# A33G53x register map
Vendor: ABOV Semiconductor Co., Ltd.; File version: 0.1
CPU: CM3 r1p0, little endian, no MPU, no FPU, 3 interrupt priority bits
Registers are 32-bit, read-write, reset 0x0 unless marked. A register's access mark holds for its fields unless they carry their own. Offsets are from the block's base; [hi:lo] are bit positions; {n}, {i} and the like mark numbered series.

## PMU — POWER MANAGEMENT UNIT
Base 0x40000000
0x00 IDR ro reset 0xCEDA0000 — Chip ID Register
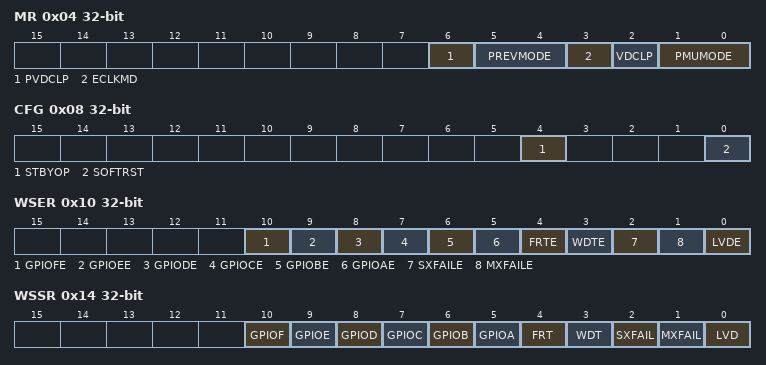
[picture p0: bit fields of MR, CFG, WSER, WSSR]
0x04 MR — PMU Mode Register
  [6] PVDCLP ro — VDC low power status of the previous state
  [5:4] PREVMODE ro — The previous MCU status before reset
  [3] ECLKMD wo — Power-down mode, External Clock Oscillator(Main/Sub) is automatically OFF or set to allow user setting
  [2] VDCLP wo — Power-down mode, VDC switched to low-power
  [1:0] PMUMODE — Indicates the current operating mode of the MCU, that the value of this mode when you write. However, writing '11' is prohibited.
0x08 CFG — PMU CONFIGURATION REGISTER
  [4] STBYOP — Output polarity of STBY pin
  [0] SOFTRST wo — Setting for internal soft-reset
0x10 WSER — PMU Wake-up Source Enable Register
  [10] GPIOFE — Setting of the wake-up by GPIOF (PD SLEEP)
  [9] GPIOEE — Setting of the wake-up by GPIOE (PD SLEEP)
  [8] GPIODE — Setting of the wake-up by GPIOD (PD SLEEP)
  [7] GPIOCE — Setting of the wake-up by GPIOC (PD SLEEP)
  [6] GPIOBE — Setting of the wake-up by GPIOB (PD SLEEP)
  [5] GPIOAE — Setting of the wake-up by GPIO (PD SLEEP)
  [4] FRTE — Setting of the wake-up by FRT (PD SLEEP)
  [3] WDTE — Setting of the wake-up by WDT (PD SLEEP)
  [2] SXFAILE — Setting of the wake-up by the Sub OSC Fail Event(SLEEP)Setting value of the wake-up by LVD (SLEEP)
  [1] MXFAILE — Setting of the wake-up by Main OSC-fail event(SLEEP)Setting value of the wake-up by Sub OSC Fail Event (SLEEP)
  [0] LVDE — Setting of the wake-up by LVD (SLEEP)Setting value of the wake-up by Main OSC Fail Event (SLEEP)
0x14 WSSR ro — PMU Wak-up Source Status Register
  [10] GPIOF — Status flag of the wake-up by GPIOF
  [9] GPIOE — Status flag of the wake-up by GPIOE
  [8] GPIOD — Status flag of the wake-up by GPIOD
  [7] GPIOC — Status flag of the wake-up by GPIOC
  [6] GPIOB — Status flag of the wake-up by GPIOB
  [5] GPIOA — Status flag of the wake-up by GPIOA
  [4] FRT — Status flag of the wake-up by FRT
  [3] WDT — Status flag of the wake-up by WDT
  [2] SXFAIL — Status flag of the wake-up by Sub OSC Fail Event
  [1] MXFAIL — Status flag of the wake-up by Main OSC Fail Event
  [0] LVD — Status flag of the wake-up by LVD
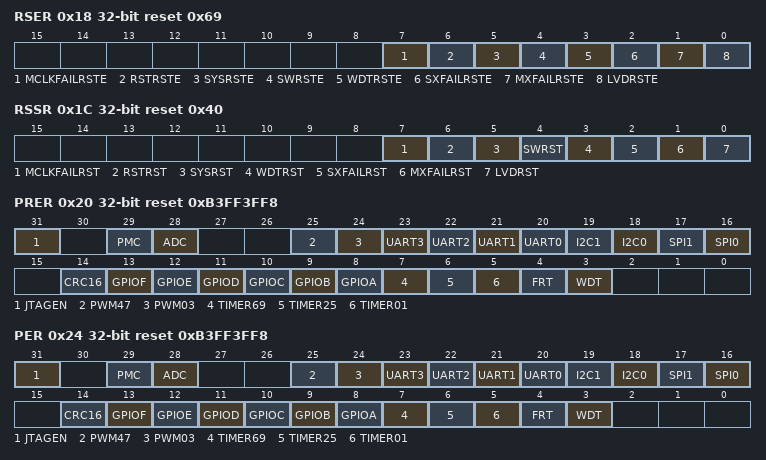
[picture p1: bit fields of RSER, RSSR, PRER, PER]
0x18 RSER reset 0x69 (reset mask 0xFB) — Reset Source Enable Register
  [7] MCLKFAILRSTE — Enable/Disable Main Clock Oscillator pin reset
  [6] RSTRSTE — Enable/Disable external nRESET pin reset
  [5] SYSRSTE — Enable/Disable SystemReset from the core
  [4] SWRSTE — Enable/Disable Software Reset in PMUCFGR
  [3] WDTRSTE — Enable/Disable WDT reset
  [2] SXFAILRSTE — Enable/Disable auxiliary oscillator failure reset
  [1] MXFAILRSTE — Enable/Disable auxiliary oscillator failure reset
  [0] LVDRSTE — Enable/Disable LVD reset
0x1C RSSR reset 0x40 (reset mask 0xFB) — Reset Source Status Register
  [7] MCLKFAILRST — Occurrence of Main Clock Oscillator pin reset
  [6] RSTRST — Occurrence of external nRESET pin reset
  [5] SYSRST — Occurrence of SystemReset from the core
  [4] SWRST — Occurrence of Software Reset in PMUCFGR
  [3] WDTRST — Occurrence of WDT reset
  [2] SXFAILRST — Occurrence of auxiliary oscillator failure reset
  [1] MXFAILRST — Occurrence of auxiliary oscillator failure reset
  [0] LVDRST — Occurrence of LVD reset
0x20 PRER reset 0xB3FF3FF8 — PMU Peripheral Event Reset Register
  [31] JTAGEN — Enable JTAG reset
  [29] PMC — Enable PMC (Port Map Controller) reset
  [28] ADC — Enable ADC reset
  [25] PWM47 — Enable PWM4, 5,6,7 reset
  [24] PWM03 — Enable PWM0, 1,2,3 reset
  [n+20] UART{n} (n=0..3) — Enable UART{n} reset
  [19] I2C1 — Enable I2C1 reset
  [18] I2C0 — Enable I2C0 reset
  [17] SPI1 — Enable SPI1 reset
  [16] SPI0 — Enable SPI0 reset
  [14] CRC16 — Enable CRC reset
  [13] GPIOF — Enable GPIOF reset
  [12] GPIOE — Enable GPIOE reset
  [11] GPIOD — Enable GPIOD reset
  [10] GPIOC — Enable GPIOC reset
  [9] GPIOB — Enable GPIOB reset
  [8] GPIOA — Enable GPIOA reset
  [7] TIMER69 — Enable TIMER6, 7,8,9 reset
  [6] TIMER25 — Enable TIMER2, 3,4,5 reset
  [5] TIMER01 — Enable TIMER0, 1 reset
  [4] FRT — Enble Free-run Timer reset
  [3] WDT — Enabled Watchdog Timer reset
0x24 PER reset 0xB3FF3FF8 — PMU Perpheral Enable Register
  [31] JTAGEN — JTAG enable - reset
  [29] PMC — Enable-Reset PMC
  [28] ADC — Enable-Reset ADC
  [25] PWM47 — Enable-Reset PWM4, 5,6,7
  [24] PWM03 — Enable-Reset PWM0, 1,2,3
  [n+20] UART{n} (n=0..3) — Enable-Reset UART{n}
  [19] I2C1 — Enable-Reset I2C1
  [18] I2C0 — Enable-Reset I2C0
  [17] SPI1 — Enable-Reset SPI1
  [16] SPI0 — Enable-Reset SPI0
  [14] CRC16 — Enable-Reset CRC16
  [13] GPIOF — Enable-Reset PMC_F, GPIOF
  [12] GPIOE — Enable-Reset PMC_E, GPIOE
  [11] GPIOD — Enable-Reset PMC_D, GPIOD
  [10] GPIOC — Enable-Reset PMC_C, GPIOC
  [9] GPIOB — Enable-Reset PMC_B, GPIOB
  [8] GPIOA — Enable-Reset PMC_A, GPIOA
  [7] TIMER69 — Enable-Reset TIMER6, 7,8,9
  [6] TIMER25 — Enable-Reset TIMER2, 3,4,5
  [5] TIMER01 — Enable-Reset TIMER0, 1
  [4] FRT — Enable-Reset Free-run Timer
  [3] WDT — Enable-Reset Watch-dog Timer
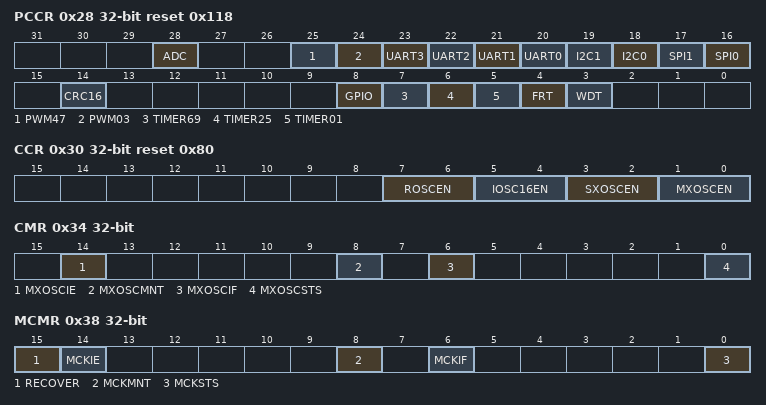
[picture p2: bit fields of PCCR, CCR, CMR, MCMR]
0x28 PCCR reset 0x118 (reset mask 0x11FF41F8) — PMU Peripheral Clock Control Register
  [28] ADC — Enable-Disable ADC clock
  [25] PWM47 — Enable-Disable PWM4, 5,6,7 clock
  [24] PWM03 — Enable-Disable PWM0, 1,2,3 clock
  [n+20] UART{n} (n=0..3) — Enable-Disable UART{n} clock
  [19] I2C1 — Enable-Disable I2C1 clock
  [18] I2C0 — Enable-Disable I2C0 clock
  [17] SPI1 — Enable-Disable SPI1 clock
  [16] SPI0 — Enable-Disable SPI0 clock
  [14] CRC16 — Enable-Disable CRC16 clock
  [8] GPIO — Enable-Disable GPIO clock
  [7] TIMER69 — Enable-Disable TIMER6, 7,8,9 clock
  [6] TIMER25 — Enable-Disable TIMER2, 3,4,5 clock
  [5] TIMER01 — Enable-Disable TIMER0, 1 clock
  [4] FRT — Enable-Disable Free-run Timer clock
  [3] WDT — Enable-Disable Watch-dog Timer clock
0x30 CCR reset 0x80 — PMU Clock Control Register
  [7:6] ROSCEN — Enable internal ring oscillator
  [5:4] IOSC16EN — Enable internal 16MHz oscillator
  [3:2] SXOSCEN — Enable external sub-crystal oscillator
  [1:0] MXOSCEN — Enable external main crystal oscillator
0x34 CMR — PMU Clock Monitoring Register
  [14] MXOSCIE — Enable-Disable the interrupt event of monitoring external main crystal oscillation
  [8] MXOSCMNT — Enable-Disable the monitoring function of external main crystal oscillator
  [6] MXOSCIF — Failure dectection flag of external main crystal oscillation (To clear this flag, write 1 to the bit)
  [0] MXOSCSTS — The oscillation status of external main crystal oscillation (To clear this flag, write 1 to the bit)
0x38 MCMR — PMU Main Clock Monitoring Register
  [15] RECOVER — Automatically switches main clock to internal ring oscillator when main clock oscillation error occurs
  [14] MCKIE — Main clock oscillation monitoring Interrupt active selection
  [8] MCKMNT — Enable main clock oscillation monitoring
  [6] MCKIF — main clock oscillation state flag
  [0] MCKSTS ro — Main clock oscillation state
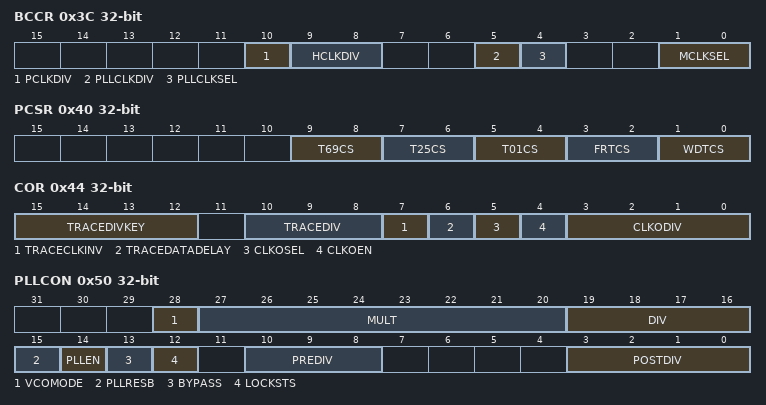
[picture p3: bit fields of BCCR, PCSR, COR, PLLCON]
0x3C BCCR — PMU BUS Clock Control Register
  [10] PCLKDIV — PCLK clock divider set
  [9:8] HCLKDIV — HCLK clock dvider set
  [5] PLLCLKDIV — PLL input clock divider
  [4] PLLCLKSEL — PLL input clock selection
  [1:0] MCLKSEL — Main clock source selection
0x40 PCSR — PMU Peripheral Clock Select Register
  [9:8] T69CS — Select the timer 6,7,8,9 input clock
  [7:6] T25CS — Select timer 2,3,4,5 input clock
  [5:4] T01CS — Select timer 0,1 input clock
  [3:2] FRTCS — Select FRT input clock
  [1:0] WDTCS — Select WDT input clock
0x44 COR — PMU Clock Output Register
  [15:12] TRACEDIVKEY wo — TRACEDIV, TRACECLK INV, TRACEDATA DELAY KEY value to use when changing field values
  [10:8] TRACEDIV — Sets the frequency of the TRACE clock. Currently only 000b is supported. If you want to change to a different value, you must use 0xB in TRACEDIVKEY.
  [7] TRACECLKINV — Inversion of TRACECLK output
  [6] TRACEDATADELAY — Delay the internal TRACE DATA output by 1/4 cycle
  [5] CLKOSEL — Select Clock Output Source
  [4] CLKOEN — Enable CLKO divider output
  [3:0] CLKODIV — set the value of the division of CLKO
0x50 PLLCON — PLL Control Register
  [28] VCOMODE — VCO Operation mode setting
  [27:20] MULT — VCO output scale setting. Determine the N1 value of the frequency equation.
  [19:16] DIV — Set the DIV value of the VCO output. Determine the N2 value of the frequency equation.
  [15] PLLRESB — PLL Reset
  [14] PLLEN — PLL Enable
  [13] BYPASS — Select PLL input clock bypass
  [12] LOCKSTS ro — PLL Lock state
  [10:8] PREDIV — Pre-Divider division control. Determine the R value of the frequency equation.
  [3:0] POSTDIV — post divider. Determine the P value of the frequency equation.
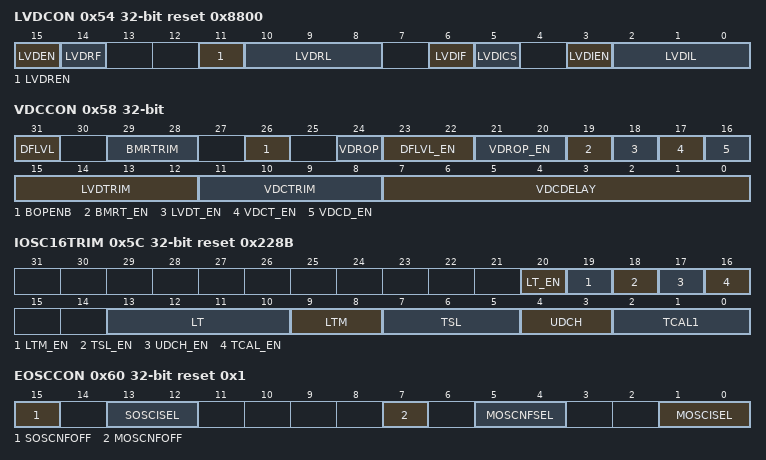
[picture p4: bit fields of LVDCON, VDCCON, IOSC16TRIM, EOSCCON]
0x54 LVDCON reset 0x8800 — LVD Control Register
  [15] LVDEN — Enable LVD
  [14] LVDRF — LVD reset flag (cleared when writing 1)
  [11] LVDREN — Enable LVD Reset
  [10:8] LVDRL — Select LVD Reset voltage level
  [6] LVDIF — LVD interrupt flag (cleared when writing 1)
  [5] LVDICS ro — LVD interrupt current status
  [3] LVDIEN — Enable LVD interrupt
  [2:0] LVDIL — Select LVD Interrupt voltage level
0x58 VDCCON — VDC Control Register
  [31] DFLVL — LVR Default level signal setting
  [29:28] BMRTRIM — BMR voltage trimming value Setting
  [26] BOPENB — BURST OFF / Pull-up Enable / Circuit OFF
  [24] VDROP — VDC Level Down Mode
  [23:22] DFLVL_EN wo — Maintain/Change DFLVL value
  [21:20] VDROP_EN wo — Maintain/Change VDROP value
  [19] BMRT_EN wo — Maintain/Change BMRTRIM value
  [18] LVDT_EN wo — Maintain/Change LVDTRIM value
  [17] VDCT_EN wo — Maintain/Change VDCTRIM value
  [16] VDCD_EN wo — Maintain/Change VDCDELAY value
  [15:12] LVDTRIM — Setting LVD (Low Voltage Detector) voltage trimming value
  [11:8] VDCTRIM — Setting VDC voltage trimming value
  [7:0] VDCDELAY — Setting VDC Output delay time during wake-up from power-down mode
0x5C IOSC16TRIM reset 0x228B — IOS16 Trimming Register
  [20] LT_EN wo — Maintain/Change LT value
  [19] LTM_EN wo — Maintain/Change LTM value
  [18] TSL_EN wo — Maintain/Change TSL value
  [17] UDCH_EN wo — Maintain/Change UDCH value
  [16] TCAL_EN wo — Maintain/Change TCAL value
  [13:10] LT — Period tuning
  [9:8] LTM — Period tuning
  [7:5] TSL — Period, Temp tuning
  [4:3] UDCH — Period, Temp tuning (default: 01)
  [2:0] TCAL1 — Temp tuning (default: 011)
0x60 EOSCCON reset 0x1 (reset mask 0xB0B2) — External Oscillator Control Register
  [15] SOSCNFOFF — Noise Filter function of SUB OSC ON/OFF
  [13:12] SOSCISEL — Current strength of SUB OSC control function
  [7] MOSCNFOFF — Noise Filter of MAIN OSC function ON/OFF
  [5:4] MOSCNFSEL — Noise Filter of MAIN OSC Function
  [1:0] MOSCISEL — Current strength of MAIN OSC control function
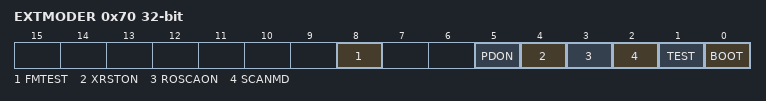
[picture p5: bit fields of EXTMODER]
0x70 EXTMODER — External Mode Read Register
  [8] FMTEST wo — Set all pins to test mode
  [5] PDON ro — Read PDON pin
  [4] XRSTON ro — Read XRSTON pin
  [3] ROSCAON ro — Read ROSCAON pin
  [2] SCANMD ro — Read SCANMD pin
  [1] TEST ro — Read TEST pin
  [0] BOOT ro — Read BOOT pin
